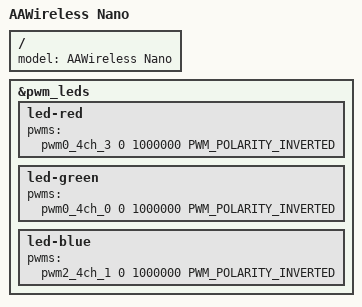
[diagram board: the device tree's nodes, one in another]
// SPDX-License-Identifier: (GPL-2.0+ OR MIT)

/dts-v1/;

#include "aaw3.dtsi"
#include <dt-bindings/pwm/pwm.h>

/ {
	model = "AAWireless Nano";
};

&pwm_leds {
	led-red {
		pwms = <&pwm0_4ch_3 0 1000000 PWM_POLARITY_INVERTED>;
	};

	led-green {
		pwms = <&pwm0_4ch_0 0 1000000 PWM_POLARITY_INVERTED>;
	};

	led-blue {
		pwms = <&pwm2_4ch_1 0 1000000 PWM_POLARITY_INVERTED>;
	};
};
